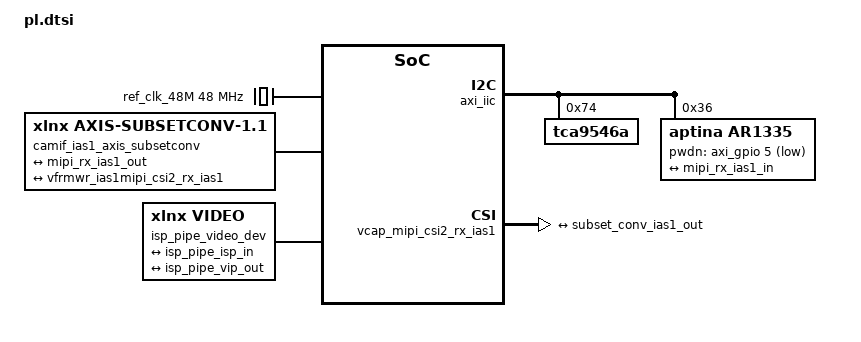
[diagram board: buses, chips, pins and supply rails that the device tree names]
/*
 * CAUTION: This file is automatically generated by Xilinx.
 * Version: XSCT 2022.1
 * Today is: Fri Nov  4 22:41:51 2022
 */


/dts-v1/;
/plugin/;
/ {
	fragment@0 {
		target = <&fpga_full>;
		overlay0: __overlay__ {
			#address-cells = <2>;
			#size-cells = <2>;
			firmware-name = "design_1_wrapper.bit.bin";
			resets = <&zynqmp_reset 116>;
		};
	};
	fragment@1 {
		target = <&amba>;
		overlay1: __overlay__ {
			afi0: afi0 {
				compatible = "xlnx,afi-fpga";
				config-afi = < 0 0>, <1 0>, <2 0>, <3 0>, <4 0>, <5 0>, <6 0>, <7 0>, <8 0>, <9 0>, <10 0>, <11 0>, <12 0>, <13 0>, <14 0xa00>, <15 0x000>;
			};
			clocking0: clocking0 {
				#clock-cells = <0>;
				assigned-clock-rates = <99999001>;
				assigned-clocks = <&zynqmp_clk 71>;
				clock-output-names = "fabric_clk";
				clocks = <&zynqmp_clk 71>;
				compatible = "xlnx,fclk";
			};
		};
	};
	fragment@2 {
		target = <&amba>;
		overlay2: __overlay__ {
			#address-cells = <2>;
			#size-cells = <2>;
			misc_clk_0: misc_clk_0 {
				#clock-cells = <0>;
				clock-frequency = <150074602>;
				compatible = "fixed-clock";
			};
			misc_clk_1: misc_clk_1 {
				#clock-cells = <0>;
				clock-frequency = <100000000>;
				compatible = "fixed-clock";
			};
			misc_clk_2: misc_clk_2 {
				#clock-cells = <0>;
				clock-frequency = <124493704>;
				compatible = "fixed-clock";
			};
			ref_clk_48M: ref_clk_48M {
				#clock-cells = <0>;
				clock-frequency = <48000000>;
				compatible = "fixed-clock";
			};
			axi_intc: interrupt-controller@a0020000 {
				#interrupt-cells = <2>;
				clock-names = "s_axi_aclk";
				clocks = <&misc_clk_0>;
				compatible = "xlnx,axi-intc-4.1", "xlnx,xps-intc-1.00.a";
				interrupt-controller ;
				interrupt-parent = <0x4>;
				interrupts = <0 89 4>;
				reg = <0x0 0xa0020000 0x0 0x10000>;
				xlnx,kind-of-intr = <0x0>;
				xlnx,num-intr-inputs = <0x9>;
			};
			camif_ias1_vfrm_wr_ias1: v_frmbuf_wr@a0040000 {
				#dma-cells = <1>;
				clock-names = "ap_clk";
				clocks = <&misc_clk_0>;
				compatible = "xlnx,v-frmbuf-wr-2.4", "xlnx,axi-frmbuf-wr-v2.2";
				interrupt-names = "interrupt";
				interrupt-parent = <&axi_intc>;
				interrupts = <0 2>;
				reg = <0x0 0xa0040000 0x0 0x10000>;
				reset-gpios = <&axi_gpio 2 1>;
				xlnx,dma-addr-width = <32>;
				xlnx,dma-align = <32>;
				xlnx,max-height = <3120>;
				xlnx,max-width = <4208>;
				xlnx,pixels-per-clock = <4>;
				xlnx,s-axi-ctrl-addr-width = <0x7>;
				xlnx,s-axi-ctrl-data-width = <0x20>;
				xlnx,vid-formats = "y8", "y10";
				xlnx,video-width = <10>;
			};
			camif_rpi_vfrm_wr_rpi: v_frmbuf_wr@a0060000 {
				#dma-cells = <1>;
				clock-names = "ap_clk";
				clocks = <&misc_clk_0>;
				compatible = "xlnx,v-frmbuf-wr-2.4", "xlnx,axi-frmbuf-wr-v2.2";
				interrupt-names = "interrupt";
				interrupt-parent = <&axi_intc>;
				interrupts = <6 2>;
				reg = <0x0 0xa0060000 0x0 0x10000>;
				reset-gpios = <&axi_gpio 3 1>;
				xlnx,dma-addr-width = <32>;
				xlnx,dma-align = <16>;
				xlnx,max-height = <2160>;
				xlnx,max-width = <3840>;
				xlnx,pixels-per-clock = <2>;
				xlnx,s-axi-ctrl-addr-width = <0x7>;
				xlnx,s-axi-ctrl-data-width = <0x20>;
				xlnx,vid-formats = "y8", "y10";
				xlnx,video-width = <10>;
			};
			isp_pipe_vfrm_rd_isp: v_frmbuf_rd@a0080000 {
				#dma-cells = <1>;
				clock-names = "ap_clk";
				clocks = <&misc_clk_0>;
				compatible = "xlnx,v-frmbuf-rd-2.4", "xlnx,axi-frmbuf-rd-v2.2";
				interrupt-names = "interrupt";
				interrupt-parent = <&axi_intc>;
				interrupts = <2 2>;
				reg = <0x0 0xa0080000 0x0 0x10000>;
				reset-gpios = <&axi_gpio 0 1>;
				xlnx,dma-addr-width = <32>;
				xlnx,dma-align = <8>;
				xlnx,max-height = <2160>;
				xlnx,max-width = <3840>;
				xlnx,pixels-per-clock = <1>;
				xlnx,s-axi-ctrl-addr-width = <0x7>;
				xlnx,s-axi-ctrl-data-width = <0x20>;
				xlnx,vid-formats = "y8", "y10";
				xlnx,video-width = <10>;
			};
			isp_pipe_vfrm_wr_isp: v_frmbuf_wr@a0090000 {
				#dma-cells = <1>;
				clock-names = "ap_clk";
				clocks = <&misc_clk_0>;
				compatible = "xlnx,v-frmbuf-wr-2.4", "xlnx,axi-frmbuf-wr-v2.2";
				interrupt-names = "interrupt";
				interrupt-parent = <&axi_intc>;
				interrupts = <5 2>;
				reg = <0x0 0xa0090000 0x0 0x10000>;
				reset-gpios = <&axi_gpio 1 1>;
				xlnx,dma-addr-width = <32>;
				xlnx,dma-align = <8>;
				xlnx,max-height = <2160>;
				xlnx,max-width = <3840>;
				xlnx,pixels-per-clock = <1>;
				xlnx,s-axi-ctrl-addr-width = <0x7>;
				xlnx,s-axi-ctrl-data-width = <0x20>;
				xlnx,vid-formats = "rgb888", "bgr888", "uyvy", "yuyv", "nv12";
				xlnx,video-width = <8>;
			};
		};
	};
	fragment@3 {
		target = <&amba>;
		overlay3: __overlay__ {
			#address-cells = <2>;
			#size-cells = <2>;
			axi_gpio: gpio@a0000000 {
				#gpio-cells = <2>;
				clock-names = "s_axi_aclk";
				clocks = <&misc_clk_0>;
				compatible = "xlnx,axi-gpio-2.0", "xlnx,xps-gpio-1.00.a";
				gpio-controller ;
				reg = <0x0 0xa0000000 0x0 0x10000>;
				xlnx,all-inputs = <0x0>;
				xlnx,all-inputs-2 = <0x0>;
				xlnx,all-outputs = <0x1>;
				xlnx,all-outputs-2 = <0x0>;
				xlnx,dout-default = <0x00000000>;
				xlnx,dout-default-2 = <0x00000000>;
				xlnx,gpio-width = <0x8>;
				xlnx,gpio2-width = <0x20>;
				xlnx,interrupt-present = <0x0>;
				xlnx,is-dual = <0x0>;
				xlnx,tri-default = <0xFFFFFFFF>;
				xlnx,tri-default-2 = <0xFFFFFFFF>;
			};
			axi_iic: i2c@a0010000 {
				#address-cells = <1>;
				#size-cells = <0>;
				clock-names = "s_axi_aclk";
				clocks = <&misc_clk_0>;
				compatible = "xlnx,axi-iic-2.1", "xlnx,xps-iic-2.00.a";
				interrupt-names = "iic2intc_irpt";
				interrupt-parent = <&axi_intc>;
				interrupts = <1 2>;
				reg = <0x0 0xa0010000 0x0 0x10000>;
				tca9546a: i2c_switcher@36 {
					compatible = "tca9546a";
					reg = <0x74>;
				};
				ar1335: camera@36 {
					compatible = "aptina,ar1335";
					reg = <0x36>;
					clocks = <&ref_clk_48M>;
					clock-names = "xclk";
					pwdn-gpios = <&axi_gpio 5 1>;
					port {
						ar1335_csi2_out: endpoint {
							remote-endpoint = <&mipi_rx_ias1_in>;
							clock-lanes = <0>;
							data-lanes = <1 2 3 4>;
						};
					};
				};
			};
			/* camif_ias1 */
			camif_ias1_mipi_rx_to_video_ias1: mipi_rx_to_video@a0030000 {
				/* This is a place holder node for a custom IP, user may need to update the entries */
				clock-names = "dphy_clk_p", "dphy_clk_n", "s00_axi_aclk";
				clocks = <&misc_clk_1>, <&misc_clk_1>, <&misc_clk_0>;
				compatible = "xlnx,mipi-rx-to-video-1.0";
				interrupt-names = "irq";
				interrupt-parent = <&axi_intc>;
				interrupts = <7 2>;
				reg = <0x0 0xa0030000 0x0 0x10000>;
				xlnx,s00-axi-addr-width = <0x7>;
				xlnx,s00-axi-data-width = <0x20>;
				ports {
					#address-cells = <1>;
					#size-cells = <0>;
					port@1 {
						reg = <1>;
						mipi_rx_ias1_out: endpoint {
							remote-endpoint = <&subset_conv_ias1_in>;
						};
					};
					port@0 {
						reg = <0>;
						mipi_rx_ias1_in: endpoint {
							data-lanes = <1 2 3 4>;
							remote-endpoint = <&ar1335_csi2_out>;
						};
					};
				};
			};
			camif_ias1_axis_subsetconv {
				compatible = "xlnx,axis-subsetconv-1.1";

				ports {
					#address-cells = <1>;
					#size-cells = <0>;

					port@0 {
						/* Sink port */
						reg = <0>;
						subset_conv_ias1_in: endpoint {
							remote-endpoint = <&mipi_rx_ias1_out>;
						};
					};
					port@1 {
						/* Source port */
						reg = <1>;
						subset_conv_ias1_out: endpoint {
							remote-endpoint = <&vfrmwr_ias1mipi_csi2_rx_ias1>;
						};
					};
				};
			};
			vcap_mipi_csi2_rx_ias1 {
				compatible = "xlnx,video";
				dma-names = "port0";
				dmas = <&camif_ias1_vfrm_wr_ias1 0>;
				vcap_portsmipi_csi2_rx_ias1: ports {
					#address-cells = <1>;
					#size-cells = <0>;
					vcap_portmipi_csi2_rx_ias1: port@0 {
						direction = "input";
						reg = <0>;
						vfrmwr_ias1mipi_csi2_rx_ias1: endpoint {
							remote-endpoint = <&subset_conv_ias1_out>;
						};
					};
				};
			};
			/* camif_rpi */
			camif_rpi_mipi_rx_to_video_rpi: mipi_rx_to_video@a0050000 {
				/* This is a place holder node for a custom IP, user may need to update the entries */
				clock-names = "dphy_clk_p", "dphy_clk_n", "s00_axi_aclk";
				clocks = <&misc_clk_1>, <&misc_clk_1>, <&misc_clk_0>;
				compatible = "xlnx,mipi-rx-to-video-1.0";
				interrupt-names = "irq";
				interrupt-parent = <&axi_intc>;
				interrupts = <8 2>;
				reg = <0x0 0xa0050000 0x0 0x10000>;
				xlnx,s00-axi-addr-width = <0x7>;
				xlnx,s00-axi-data-width = <0x20>;
			};
			/* isp_pipe */
			isp_pipe_isp: xil_isp_lite@a0070000 {
				/* This is a place holder node for a custom IP, user may need to update the entries */
				clock-names = "pclk", "s00_axi_aclk";
				clocks = <&misc_clk_2>, <&misc_clk_0>;
				compatible = "xlnx,xil-isp-lite-1.0";
				interrupt-names = "irq";
				interrupt-parent = <&axi_intc>;
				interrupts = <3 2>;
				reg = <0x0 0xa0070000 0x0 0x10000>;
				xlnx,s00-axi-addr-width = <0xe>;
				xlnx,s00-axi-data-width = <0x20>;
				ports {
					#address-cells = <1>;
					#size-cells = <0>;
					port@0 {
						direction = "input";
						reg = <0>;
						isp_pipe_isp_in: endpoint {
							remote-endpoint = <&isp_pipe_video_dev_out>;
						};
					};
					port@1 {
						direction = "output";
						reg = <1>;
						isp_pipe_isp_out: endpoint {
							remote-endpoint = <&isp_pipe_vip_in>;
						};
					};
				};
			};
			isp_pipe_vip: xil_vip@a00a0000 {
				/* This is a place holder node for a custom IP, user may need to update the entries */
				clock-names = "pclk", "s00_axi_aclk";
				clocks = <&misc_clk_2>, <&misc_clk_0>;
				compatible = "xlnx,xil-vip-1.0";
				interrupt-names = "irq";
				interrupt-parent = <&axi_intc>;
				interrupts = <4 2>;
				reg = <0x0 0xa00a0000 0x0 0x10000>;
				xlnx,s00-axi-addr-width = <0xc>;
				xlnx,s00-axi-data-width = <0x20>;
				ports {
					#address-cells = <1>;
					#size-cells = <0>;
					port@0 {
						direction = "input";
						reg = <0>;
						isp_pipe_vip_in: endpoint {
							remote-endpoint = <&isp_pipe_isp_out>;
						};
					};
					port@1 {
						direction = "output";
						reg = <1>;
						isp_pipe_vip_out: endpoint {
							remote-endpoint = <&isp_pipe_video_dev_in>;
						};
					};
				};
			};
			//isp_pipe_axis_subsetconv {
			//	compatible = "xlnx,axis-subsetconv-1.1";

			//	ports {
			//		#address-cells = <1>;
			//		#size-cells = <0>;

			//		port@0 {
			//			/* Sink port */
			//			reg = <0>;
			//			subset_conv_isp_in: endpoint {
			//				remote-endpoint = <&isp_pipe_video_dev_out>;
			//			};
			//		};
			//		port@1 {
			//			/* Source port */
			//			reg = <1>;
			//			subset_conv_isp_out: endpoint {
			//				remote-endpoint = <&isp_pipe_video_dev_in>;
			//			};
			//		};
			//	};
			//};
			isp_pipe_video_dev {
				compatible = "xlnx,video";
				dmas = <&isp_pipe_vfrm_rd_isp 0>, <&isp_pipe_vfrm_wr_isp 0>;
				dma-names = "port0", "port1";
				ports {
					#address-cells = <1>;
					#size-cells = <0>;
					port@0 {
						direction = "output";
						reg = <0>;
						isp_pipe_video_dev_out: endpoint {
							remote-endpoint = <&isp_pipe_isp_in>;
							//remote-endpoint = <&subset_conv_isp_in>;
						};
					};
					port@1 {
						direction = "input";
						reg = <1>;
						isp_pipe_video_dev_in: endpoint {
							remote-endpoint = <&isp_pipe_vip_out>;
							//remote-endpoint = <&subset_conv_isp_out>;
						};
					};
				};
			};
		};
	};
};
